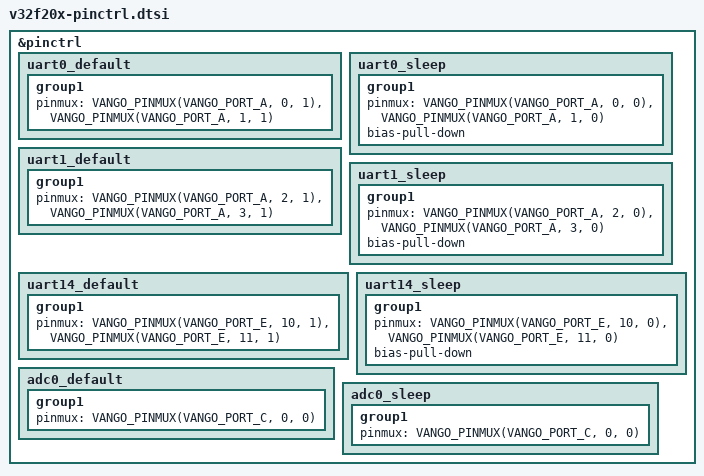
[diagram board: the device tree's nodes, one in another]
/*
 * V32F20x SOC Pinctrl Definitions
 * Copyright (c) 2024 Vango Technologies
 * SPDX-License-Identifier: Apache-2.0
 */

&pinctrl {
    /* UART0 */
    uart0_default: uart0_default {
        group1 {
            pinmux = <VANGO_PINMUX(VANGO_PORT_A, 0, 1)>,
                     <VANGO_PINMUX(VANGO_PORT_A, 1, 1)>;
        };
    };
    uart0_sleep: uart0_sleep {
        group1 {
            pinmux = <VANGO_PINMUX(VANGO_PORT_A, 0, 0)>,
                     <VANGO_PINMUX(VANGO_PORT_A, 1, 0)>;
            bias-pull-down;
        };
    };

    /* UART1 */
    uart1_default: uart1_default {
        group1 {
            pinmux = <VANGO_PINMUX(VANGO_PORT_A, 2, 1)>,
                     <VANGO_PINMUX(VANGO_PORT_A, 3, 1)>;
        };
    };
    uart1_sleep: uart1_sleep {
        group1 {
            pinmux = <VANGO_PINMUX(VANGO_PORT_A, 2, 0)>,
                     <VANGO_PINMUX(VANGO_PORT_A, 3, 0)>;
            bias-pull-down;
        };
    };

    /* UART14 */
    uart14_default: uart14_default {
        group1 {
            pinmux = <VANGO_PINMUX(VANGO_PORT_E, 10, 1)>,
                     <VANGO_PINMUX(VANGO_PORT_E, 11, 1)>;
        };
    };
    uart14_sleep: uart14_sleep {
        group1 {
            pinmux = <VANGO_PINMUX(VANGO_PORT_E, 10, 0)>,
                     <VANGO_PINMUX(VANGO_PORT_E, 11, 0)>;
            bias-pull-down;
        };
    };

    /* ADC0 */
    adc0_default: adc0_default {
        group1 {
            pinmux = <VANGO_PINMUX(VANGO_PORT_C, 0, 0)>; /* Analog mode */
        };
    };
    adc0_sleep: adc0_sleep {
        group1 {
            pinmux = <VANGO_PINMUX(VANGO_PORT_C, 0, 0)>;
        };
    };
};
